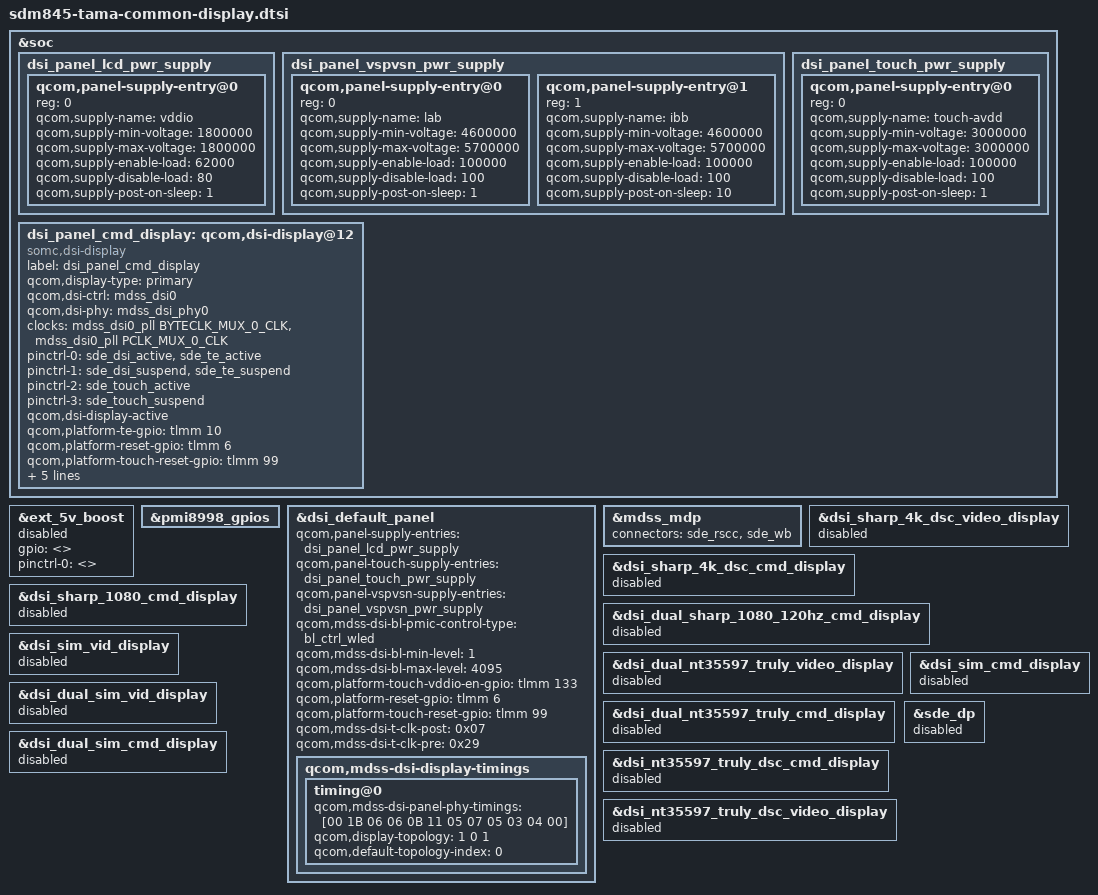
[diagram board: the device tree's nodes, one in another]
/* Copyright (c) 2015-2017, The Linux Foundation. All rights reserved.
 *
 * This program is free software; you can redistribute it and/or modify
 * it under the terms of the GNU General Public License version 2 and
 * only version 2 as published by the Free Software Foundation.
 *
 * This program is distributed in the hope that it will be useful,
 * but WITHOUT ANY WARRANTY; without even the implied warranty of
 * MERCHANTABILITY or FITNESS FOR A PARTICULAR PURPOSE.  See the
 * GNU General Public License for more details.
 */
/*
 * Copyright (C) 2017 Sony Mobile Communications Inc.
 *
 * This program is free software; you can redistribute it and/or modify
 * it under the terms of the GNU General Public License version 2, as
 * published by the Free Software Foundation.
 */

&soc {
	dsi_panel_lcd_pwr_supply: dsi_panel_lcd_pwr_supply {
		#address-cells = <1>;
		#size-cells = <0>;

		qcom,panel-supply-entry@0 {
			reg = <0>;
			qcom,supply-name = "vddio";
			qcom,supply-min-voltage = <1800000>;
			qcom,supply-max-voltage = <1800000>;
			qcom,supply-enable-load = <62000>;
			qcom,supply-disable-load = <80>;
			qcom,supply-post-on-sleep = <1>;
		};
	};

	dsi_panel_vspvsn_pwr_supply: dsi_panel_vspvsn_pwr_supply {
		#address-cells = <1>;
		#size-cells = <0>;

		qcom,panel-supply-entry@0 {
			reg = <0>;
			qcom,supply-name = "lab";
			qcom,supply-min-voltage = <4600000>;
			qcom,supply-max-voltage = <5700000>;
			qcom,supply-enable-load = <100000>;
			qcom,supply-disable-load = <100>;
			qcom,supply-post-on-sleep = <1>;
		};

		qcom,panel-supply-entry@1 {
			reg = <1>;
			qcom,supply-name = "ibb";
			qcom,supply-min-voltage = <4600000>;
			qcom,supply-max-voltage = <5700000>;
			qcom,supply-enable-load = <100000>;
			qcom,supply-disable-load = <100>;
			qcom,supply-post-on-sleep = <10>;
		};
	};

	dsi_panel_touch_pwr_supply: dsi_panel_touch_pwr_supply {
		#address-cells = <1>;
		#size-cells = <0>;

		qcom,panel-supply-entry@0 {
			reg = <0>;
			qcom,supply-name = "touch-avdd";
			qcom,supply-min-voltage = <3000000>;
			qcom,supply-max-voltage = <3000000>;
			qcom,supply-enable-load = <100000>;
			qcom,supply-disable-load = <100>;
			qcom,supply-post-on-sleep = <1>;
		};
	};

	dsi_panel_cmd_display: qcom,dsi-display@12 {
		compatible = "somc,dsi-display";
		label = "dsi_panel_cmd_display";
		qcom,display-type = "primary";

		qcom,dsi-ctrl = <&mdss_dsi0>;
		qcom,dsi-phy = <&mdss_dsi_phy0>;
		clocks = <&mdss_dsi0_pll BYTECLK_MUX_0_CLK>,
			<&mdss_dsi0_pll PCLK_MUX_0_CLK>;
		clock-names = "src_byte_clk", "src_pixel_clk";

		pinctrl-names = "panel_active", "panel_suspend",
				"sde_touch_active", "sde_touch_suspend";
		pinctrl-0 = <&sde_dsi_active &sde_te_active>;
		pinctrl-1 = <&sde_dsi_suspend &sde_te_suspend>;
		pinctrl-2 = <&sde_touch_active>;
		pinctrl-3 = <&sde_touch_suspend>;

		qcom,dsi-display-active;

		qcom,platform-te-gpio = <&tlmm 10 0>;
		qcom,platform-reset-gpio = <&tlmm 6 0>;
		/delete-property/ qcom,panel-mode-gpio;
		qcom,platform-touch-reset-gpio = <&tlmm 99 0>;
		qcom,dsi-panel = <&dsi_default_panel>;
		vddio-supply = <&pm8998_l14>;
		touch-avdd-supply = <&pm8998_l28>;
		lab-supply = <&lab_regulator>;
		ibb-supply = <&ibb_regulator>;
	};
};

&ext_5v_boost {
	status = "disabled";
	gpio = <>;
	pinctrl-0 = <>;
};

&pmi8998_gpios {
	/delete-node/ usb2_ext_5v_boost;
};

&dsi_default_panel {
	qcom,panel-supply-entries = <&dsi_panel_lcd_pwr_supply>;
	qcom,panel-touch-supply-entries = <&dsi_panel_touch_pwr_supply>;
	qcom,panel-vspvsn-supply-entries = <&dsi_panel_vspvsn_pwr_supply>;
	qcom,mdss-dsi-bl-pmic-control-type = "bl_ctrl_wled";
	qcom,mdss-dsi-bl-min-level = <1>;
	qcom,mdss-dsi-bl-max-level = <4095>;
	qcom,platform-touch-vddio-en-gpio = <&tlmm 133 0>;
	qcom,platform-reset-gpio = <&tlmm 6 0>;
	qcom,platform-touch-reset-gpio = <&tlmm 99 0>;
	qcom,mdss-dsi-t-clk-post = <0x07>;
	qcom,mdss-dsi-t-clk-pre = <0x29>;
	qcom,mdss-dsi-display-timings {
		timing@0 {
			qcom,mdss-dsi-panel-phy-timings = [00 1B 06 06 0B 11 05 07 05 03 04 00];
			qcom,display-topology = <1 0 1>;
			qcom,default-topology-index = <0>;
		};
	};
};

&mdss_mdp {
	connectors = <&sde_rscc &sde_wb>;
};

&dsi_sharp_4k_dsc_video_display {
	/delete-property/ qcom,dsi-display-active;
	status = "disabled";
};

&dsi_sharp_4k_dsc_cmd_display {
	/delete-property/ qcom,dsi-display-active;
	status = "disabled";
};

&dsi_sharp_1080_cmd_display {
	/delete-property/ qcom,dsi-display-active;
	status = "disabled";
};

&dsi_dual_sharp_1080_120hz_cmd_display {
	/delete-property/ qcom,dsi-display-active;
	status = "disabled";
};

&dsi_dual_nt35597_truly_video_display {
	/delete-property/ qcom,dsi-display-active;
	status = "disabled";
};

&dsi_dual_nt35597_truly_cmd_display {
	/delete-property/ qcom,dsi-display-active;
	status = "disabled";
};

&dsi_nt35597_truly_dsc_cmd_display {
	/delete-property/ qcom,dsi-display-active;
	status = "disabled";
};

&dsi_nt35597_truly_dsc_video_display {
	/delete-property/ qcom,dsi-display-active;
	status = "disabled";
};

&dsi_sim_vid_display {
	/delete-property/ qcom,dsi-display-active;
	status = "disabled";
};

&dsi_dual_sim_vid_display {
	/delete-property/ qcom,dsi-display-active;
	status = "disabled";
};

&dsi_sim_cmd_display {
	/delete-property/ qcom,dsi-display-active;
	status = "disabled";
};

&dsi_dual_sim_cmd_display {
	/delete-property/ qcom,dsi-display-active;
	status = "disabled";
};

&sde_dp {
	/delete-property/ qcom,dp-usbpd-detection;
	status = "disabled";
};

